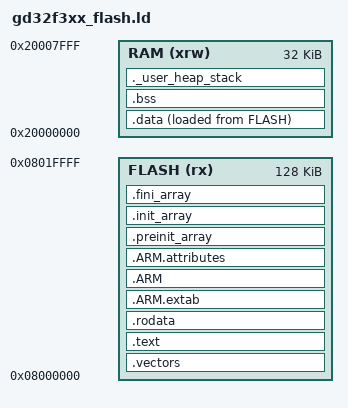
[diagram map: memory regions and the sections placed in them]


ENTRY(Reset_Handler)

/* Specify the memory areas according to your chips*/
MEMORY
{
  FLASH (rx)      : ORIGIN = 0x08000000, LENGTH = 128K
  RAM (xrw)       : ORIGIN = 0x20000000, LENGTH = 32K
}

/* Define output sections */
SECTIONS
{
  _Min_Stack_Size = 0x400; /* required amount of stack */
  _Min_Heap_Size = 0x200;      /* required amount of heap  */
  /* The startup code goes first into FLASH */
  .vectors :
  {
    . = ALIGN(4);
    KEEP(*(.vectors)) /* Startup code */
    . = ALIGN(4);
  } >FLASH

  /* The program code and other data goes into FLASH */
  .text :
  {
    . = ALIGN(4);
    *(.text)           /* .text sections (code) */
    *(.text*)          /* .text* sections (code) */
    *(.glue_7)         /* glue arm to thumb code */
    *(.glue_7t)        /* glue thumb to arm code */
    *(.eh_frame)

    KEEP (*(.init))
    KEEP (*(.fini))

    . = ALIGN(4);
    _etext = .;        /* define a global symbols at end of code */
  } >FLASH

  /* Constant data goes into FLASH */
  .rodata :
  {
    . = ALIGN(4);
    *(.rodata)         /* .rodata sections (constants, strings, etc.) */
    *(.rodata*)        /* .rodata* sections (constants, strings, etc.) */
    . = ALIGN(4);
  } >FLASH

  .ARM.extab : 
  { 
    *(.ARM.extab* .gnu.linkonce.armextab.*) 
  } >FLASH
  .ARM : {
    __exidx_start = .;
    *(.ARM.exidx*)
    __exidx_end = .;
  } >FLASH
  .ARM.attributes : { *(.ARM.attributes) } > FLASH

  .preinit_array :
  {
    PROVIDE_HIDDEN (__preinit_array_start = .);
    KEEP (*(.preinit_array*))
    PROVIDE_HIDDEN (__preinit_array_end = .);
  } >FLASH
  .init_array :
  {
    PROVIDE_HIDDEN (__init_array_start = .);
    KEEP (*(SORT(.init_array.*)))
    KEEP (*(.init_array*))
    PROVIDE_HIDDEN (__init_array_end = .);
  } >FLASH
  .fini_array :
  {
    PROVIDE_HIDDEN (__fini_array_start = .);
    KEEP (*(.fini_array*))
    KEEP (*(SORT(.fini_array.*)))
    PROVIDE_HIDDEN (__fini_array_end = .);
  } >FLASH

  /* used by the startup to initialize data */
  _sidata = LOADADDR(.data);

  /* Initialized data sections goes into RAM, load LMA copy after code */
  .data : 
  {
    . = ALIGN(4);
    _sdata = .;        /* create a global symbol at data start */
    *(.data)           /* .data sections */
    *(.data*)          /* .data* sections */

    . = ALIGN(4);
    _edata = .;        /* define a global symbol at data end */
  } >RAM AT> FLASH

  /* Uninitialized data section */
  . = ALIGN(4);
  .bss :
  {
    /* This is used by the startup in order to initialize the .bss secion */
    _sbss = .;         /* define a global symbol at bss start */
    __bss_start__ = _sbss;
    *(.bss)
    *(.bss*)
    *(COMMON)

    . = ALIGN(4);
    _ebss = .;         /* define a global symbol at bss end */
    __bss_end__ = _ebss;
  } >RAM

  /* User_heap_stack section, used to check that there is enough RAM left */
  ._user_heap_stack :
  {
    . = ALIGN(8);
    PROVIDE ( end = . );
    PROVIDE ( _end = . );
    . = . + _Min_Heap_Size;
    PROVIDE( _heap_end = . );
    . = . + _Min_Stack_Size;
    PROVIDE( _sp = . ); 
  } >RAM AT>RAM

  
}

GROUP(libgcc.a libc.a libm.a libnosys.a)
